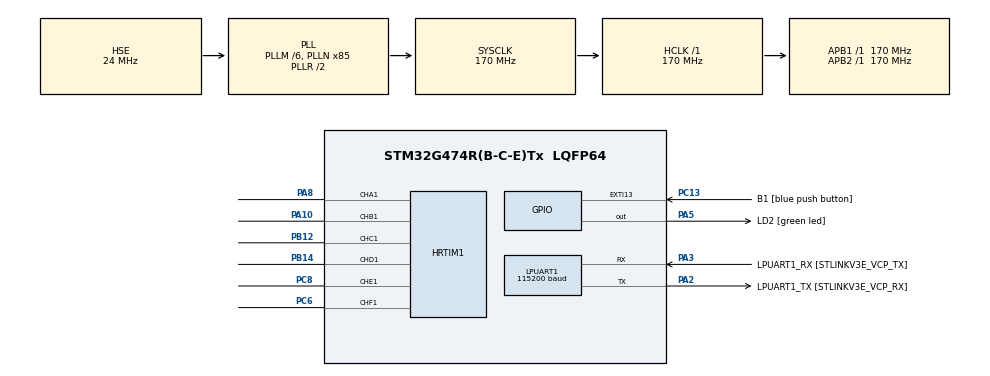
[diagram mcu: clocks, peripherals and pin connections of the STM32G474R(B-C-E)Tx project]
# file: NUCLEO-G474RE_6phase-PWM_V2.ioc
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Mcu.Family=STM32G4
HRTIM1.CompareValue1-Output_TA1=14166/6
HRTIM1.NumberSetSource1-Output_TE1=1
PB12.GPIO_Speed_High_Default=GPIO_SPEED_FREQ_LOW
RCC.CortexFreq_Value=170000000
HRTIM1.ResetTrigger2-Output_TF1=HRTIM_TIMRESETTRIGGER_OTHER4_CMP1
HRTIM1.CompareUnit2-Output_TB1=HRTIM_COMPAREUNIT_2
PC6.GPIO_Speed_High_Default=GPIO_SPEED_FREQ_LOW
HRTIM1.ResetTrigger1-Output_TD1=HRTIM_TIMRESETTRIGGER_OTHER3_CMP1
HRTIM1.CompareValue2-Output_TD1=50
PA14.GPIO_Label=T_SWCLK
HRTIM1.CompareValue1-Output_TB1=14166/6
HRTIM1.NumberSetSource1-Output_TD1=1
LPUART1.WordLength=UART_WORDLENGTH_8B
PC13.GPIO_Label=B1 [blue push button]
HRTIM1.CompareUnit2-Output_TC1=HRTIM_COMPAREUNIT_2
HRTIM1.CompareUnit4-Output_TF1=HRTIM_COMPAREUNIT_4
RCC.SYSCLKSource=RCC_SYSCLKSOURCE_PLLCLK
ProjectManager.StackSize=0x400
HRTIM1.ResetTrigger1-Output_TE1=HRTIM_TIMRESETTRIGGER_OTHER4_CMP1
HRTIM1.CompareValue2-Output_TE1=50
HRTIM1.NumberSetSource1-Output_TC1=1
HRTIM1.NumberResetSource1-Output_TF1=1
HRTIM1.CompareUnit2-Output_TD1=HRTIM_COMPAREUNIT_2
HRTIM1.CompareUnit4-Output_TE1=HRTIM_COMPAREUNIT_4
HRTIM1.CompareValue2-Output_TF1=50
HRTIM1.Periode_MASTER=14166
HRTIM1.ResetTrigger1-Output_TF1=HRTIM_TIMRESETTRIGGER_OTHER4_CMP1
RCC.HCLKFreq_Value=170000000
RCC.APB2TimFreq_Value=170000000
HRTIM1.NumberSetSource1-Output_TB1=1
HRTIM1.CompareUnit2-Output_TE1=HRTIM_COMPAREUNIT_2
RCC.AHBFreq_Value=170000000
HRTIM1.NumberResetSource1-Output_TE1=1
VP_HRTIM1_VS_hrtimMasterTimerNoOutput.Mode=MasterTimer
HRTIM1.CompareUnit4-Output_TD1=HRTIM_COMPAREUNIT_4
NVIC.EXTI15_10_IRQn=true\:0\:0\:false\:false\:true\:true\:true
RCC.HSE_VALUE=24000000
PB3.Mode=JTAG_5_pins
HRTIM1.CompareValue4-Output_TF1=14166/3
HRTIM1.ResetTrigger3-Output_TF1=HRTIM_TIMRESETTRIGGER_OTHER4_CMP4
HRTIM1.ResetOutput1_Source1-Output_TF1=HRTIM_OUTPUTRESET_TIMCMP4
PA15.Mode=JTAG_5_pins
RCC.ADC12Freq_Value=170000000
RCC.RTCClockSelection=RCC_RTCCLKSOURCE_LSE
HRTIM1.CompareUnit1-Output_TC1=HRTIM_COMPAREUNIT_1
HRTIM1.NumberSetSource1-Output_TA1=1
PB4.Mode=JTAG_5_pins
PC14-OSC32_IN.Mode=LSE-External-Oscillator
HRTIM1.NumberResetSource1-Output_TD1=1
HRTIM1.CompareUnit2-Output_TF1=HRTIM_COMPAREUNIT_2
PA14.Mode=JTAG_5_pins
PB14.Mode=Output_TD1
HRTIM1.PrescalerRatio_MASTER=HRTIM_PRESCALERRATIO_DIV1
VP_SYS_VS_DBSignals.Mode=DisableDeadBatterySignals
HRTIM1.CompareValue4-Output_TE1=14166/3
PA8.Signal=HRTIM1_CHA1
HRTIM1.CompareUnit1-Output_TD1=HRTIM_COMPAREUNIT_1
HRTIM1.ResetOutput1_Source1-Output_TE1=HRTIM_OUTPUTRESET_TIMCMP4
HRTIM1.NumberResetSource1-Output_TC1=1
HRTIM1.CompareValue2-Output_TA1=50
HRTIM1.ResetTrigger1-Output_TA1=HRTIM_TIMRESETTRIGGER_MASTER_PER
Mcu.Package=LQFP64
HRTIM1.CompareValue4-Output_TD1=14166/3
PB12.Mode=Output_TC1
HRTIM1.ResetOutput1_Source1-Output_TD1=HRTIM_OUTPUTRESET_TIMCMP4
PA2.GPIO_Label=LPUART1_TX [STLINKV3E_VCP_RX]
PA10.Signal=HRTIM1_CHB1
PA15.Signal=SYS_JTDI
HRTIM1.NumberResetTrigger-Output_TE1=1
HRTIM1.NumberResetSource1-Output_TB1=1
HRTIM1.ResetTrigger1-Output_TB1=HRTIM_TIMRESETTRIGGER_OTHER1_CMP1
HRTIM1.CompareValue4-Output_TC1=14166/3
HRTIM1.CompareValue2-Output_TB1=50
HRTIM1.SetOutput1_Source2-Output_TA1=HRTIM_OUTPUTSET_MASTERPER
RCC.APB1TimFreq_Value=170000000
HRTIM1.ResetOutput1_Source1-Output_TC1=HRTIM_OUTPUTRESET_TIMCMP4
HRTIM1.CompareUnit1-Output_TB1=HRTIM_COMPAREUNIT_1
PF1-OSC_OUT.Mode=HSE-External-Oscillator
HRTIM1.NumberResetTrigger-Output_TF1=1
PF1-OSC_OUT.Signal=RCC_OSC_OUT
HRTIM1.CompareUnit2-MasterTimer=HRTIM_COMPAREUNIT_2
RCC.HSI48_VALUE=48000000
HRTIM1.CompareUnit1-Output_TA1=HRTIM_COMPAREUNIT_1
HRTIM1.ResetTrigger1-Output_TC1=HRTIM_TIMRESETTRIGGER_OTHER2_CMP1
PB4.Signal=SYS_JTRST
HRTIM1.CompareValue4-Output_TB1=14166/3
PA3.Signal=LPUART1_RX
HRTIM1.NumberResetSource1-Output_TA1=1
HRTIM1.CompareValue2-Output_TC1=50
HRTIM1.SetOutput1_Source2-Output_TB1=HRTIM_OUTPUTSET_TIMBEV1_TIMACMP1
PB3.GPIO_Label=T_SWO
HRTIM1.SetOutput1_Source2-Output_TD1=HRTIM_OUTPUTSET_TIMPER
PA8.GPIO_Speed_High_Default=GPIO_SPEED_FREQ_LOW
RCC.PLLSourceVirtual=RCC_PLLSOURCE_HSE
PC15-OSC32_OUT.Mode=LSE-External-Oscillator
HRTIM1.ResetOutput1_Source1-Output_TB1=HRTIM_OUTPUTRESET_TIMCMP4
HRTIM1.SetOutput1_Source1-Output_TA1=HRTIM_OUTPUTSET_TIMCMP2
PA10.Mode=Output_TB1
HRTIM1.NumberResetTrigger-Output_TC1=1
HRTIM1.CompareValue4-Output_TA1=14166/3
PC13.Signal=GPXTI13
HRTIM1.SetOutput1_Source2-Output_TC1=HRTIM_OUTPUTSET_TIMPER
HRTIM1.SetOutput1_Source2-Output_TE1=HRTIM_OUTPUTSET_TIMPER
HRTIM1.ModeTimeBase-Output_TD1=HRTIM_MODE_SINGLESHOT_RETRIGGERABLE
PC8.Signal=HRTIM1_CHE1
PC6.Signal=HRTIM1_CHF1
RCC.EXTERNAL_CLOCK_VALUE=12288000
PA10.GPIO_Speed_High_Default=GPIO_SPEED_FREQ_LOW
HRTIM1.NumberUpdateTrigger-Output_TD1=0
HRTIM1.NumberResetTrigger-Output_TD1=1
PC14-OSC32_IN.Signal=RCC_OSC32_IN
HRTIM1.ResetOutput1_Source1-Output_TA1=HRTIM_OUTPUTRESET_TIMCMP4
HRTIM1.PrescalerRatio_TD=HRTIM_PRESCALERRATIO_DIV1
HRTIM1.PrescalerRatio_TE=HRTIM_PRESCALERRATIO_DIV1
HRTIM1.PrescalerRatio_TF=HRTIM_PRESCALERRATIO_DIV1
HRTIM1.SetOutput1_Source2-Output_TF1=HRTIM_OUTPUTSET_TIMPER
HRTIM1.ModeTimeBase-Output_TE1=HRTIM_MODE_SINGLESHOT_RETRIGGERABLE
HRTIM1.PrescalerRatio_TA=HRTIM_PRESCALERRATIO_DIV1
HRTIM1.CompareUnit1-Output_TE1=HRTIM_COMPAREUNIT_1
HRTIM1.PrescalerRatio_TB=HRTIM_PRESCALERRATIO_DIV1
HRTIM1.PrescalerRatio_TC=HRTIM_PRESCALERRATIO_DIV1
PA3.Mode=Asynchronous
PA13.Signal=SYS_JTMS-SWDIO
HRTIM1.NumberResetTrigger-Output_TA1=1
ProjectManager.TargetToolchain=STM32CubeIDE
PC6.Mode=Output_TF1
HRTIM1.CompareUnit1-Output_TF1=HRTIM_COMPAREUNIT_1
HRTIM1.ModeTimeBase-Output_TF1=HRTIM_MODE_SINGLESHOT_RETRIGGERABLE
RCC.USBFreq_Value=170000000
PC15-OSC32_OUT.Signal=RCC_OSC32_OUT
PF0-OSC_IN.Mode=HSE-External-Oscillator
HRTIM1.CompareValue1-MasterTimer=1700
HRTIM1.CompareValue2-MasterTimer=1700*6
PB14.Signal=HRTIM1_CHD1
HRTIM1.NumberResetTrigger-Output_TB1=1
PA5.Signal=GPIO_Output
board=NUCLEO-G474RE
RCC.VCOOutputFreq_Value=340000000
RCC.ADC345Freq_Value=170000000
HRTIM1.ResetTrigger2-Output_TB1=HRTIM_TIMRESETTRIGGER_UPDATE
RCC.APB2Freq_Value=170000000
HRTIM1.CompareValue1-Output_TE1=14166/6
HRTIM1.SetOutput1_Source1-Output_TF1=HRTIM_OUTPUTSET_TIMCMP2
HRTIM1.CompareUnit4-Output_TC1=HRTIM_COMPAREUNIT_4
PA13.Mode=JTAG_5_pins
HRTIM1.ResetTrigger2-Output_TA1=HRTIM_TIMRESETTRIGGER_UPDATE
Mcu.Name=STM32G474R(B-C-E)Tx
HRTIM1.SetOutput1_Source1-Output_TD1=HRTIM_OUTPUTSET_TIMCMP2
HRTIM1.CompareValue1-Output_TF1=14166/6
LPUART1.BaudRate=115200
PA2.Signal=LPUART1_TX
PA13.GPIO_Label=T_SWDIO
HRTIM1.SetOutput1_Source1-Output_TE1=HRTIM_OUTPUTSET_TIMCMP2
HRTIM1.CompareUnit4-Output_TB1=HRTIM_COMPAREUNIT_4
PC8.Mode=Output_TE1
PC8.GPIO_Speed_High_Default=GPIO_SPEED_FREQ_LOW
PB3.Signal=SYS_JTDO-SWO
RCC.SYSCLKFreq_VALUE=170000000
HRTIM1.ModeTimeBase-Output_TA1=HRTIM_MODE_SINGLESHOT_RETRIGGERABLE
PA5.GPIO_Label=LD2 [green led]
HRTIM1.SetOutput1_Source1-Output_TC1=HRTIM_OUTPUTSET_TIMCMP2
HRTIM1.CompareValue1-Output_TC1=14166/6
PA14.Signal=SYS_JTCK-SWCLK
ProjectManager.HeapSize=0x200
HRTIM1.CompareUnit4-Output_TA1=HRTIM_COMPAREUNIT_4
RCC.HSI_VALUE=16000000
NVIC.PriorityGroup=NVIC_PRIORITYGROUP_4
RCC.PLLM=RCC_PLLM_DIV6
RCC.PLLN=85
PA2.Mode=Asynchronous
PA8.Mode=Output_TA1
HRTIM1.NumberSetSource1-Output_TF1=1
PB14.GPIO_Speed_High_Default=GPIO_SPEED_FREQ_LOW
PF0-OSC_IN.Signal=RCC_OSC_IN
HRTIM1.ResetTrigger2-Output_TC1=HRTIM_TIMRESETTRIGGER_OTHER2_CMP1
HRTIM1.CompareValue1-Output_TD1=14166/6
RCC.APB1Freq_Value=170000000
HRTIM1.SetOutput1_Source1-Output_TB1=HRTIM_OUTPUTSET_TIMCMP2
HRTIM1.SetOutput1_Source3-Output_TA1=HRTIM_OUTPUTSET_MASTERPER
HRTIM1.Periode_TA=14166
HRTIM1.CompareUnit1-MasterTimer=HRTIM_COMPAREUNIT_1
HRTIM1.Periode_TB=14166
HRTIM1.CompareUnit2-Output_TA1=HRTIM_COMPAREUNIT_2
HRTIM1.Periode_TC=14166
HRTIM1.Periode_TD=14166
PB12.Signal=HRTIM1_CHC1
HRTIM1.Periode_TE=14166
HRTIM1.Periode_TF=14166
PA3.GPIO_Label=LPUART1_RX [STLINKV3E_VCP_TX]

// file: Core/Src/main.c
/* USER CODE BEGIN Header */
/**
  ******************************************************************************
  * @file           : main.c
  * @brief          : Main program body
  ******************************************************************************
  * @attention
  *
  * <h2><center>&copy; Copyright (c) 2021 STMicroelectronics.
  * All rights reserved.</center></h2>
  *
  * This software component is licensed by ST under BSD 3-Clause license,
  * the "License"; You may not use this file except in compliance with the
  * License. You may obtain a copy of the License at:
  *                        opensource.org/licenses/BSD-3-Clause
  *
  ******************************************************************************
  */
/* USER CODE END Header */
#include "main.h"

HRTIM_HandleTypeDef hhrtim1;

UART_HandleTypeDef hlpuart1;

void SystemClock_Config(void);
static void MX_GPIO_Init(void);
static void MX_LPUART1_UART_Init(void);
static void MX_HRTIM1_Init(void);

int main(void)
{

  /* MCU Configuration--------------------------------------------------------*/

  /* Reset of all peripherals, Initializes the Flash interface and the Systick. */
  HAL_Init();

  /* Configure the system clock */
  SystemClock_Config();

  /* Initialize all configured peripherals */
  MX_GPIO_Init();
  MX_LPUART1_UART_Init();
  MX_HRTIM1_Init();
  /* USER CODE BEGIN 2 */

  HAL_HRTIM_WaveformOutputStart(&hhrtim1, HRTIM_OUTPUT_TA1 | HRTIM_OUTPUT_TB1 | HRTIM_OUTPUT_TC1 | HRTIM_OUTPUT_TD1 | HRTIM_OUTPUT_TE1 | HRTIM_OUTPUT_TF1);
  HAL_HRTIM_WaveformCountStart_IT(&hhrtim1, HRTIM_TIMERID_MASTER | HRTIM_TIMERID_TIMER_A | HRTIM_TIMERID_TIMER_B | HRTIM_TIMERID_TIMER_C | HRTIM_TIMERID_TIMER_D | HRTIM_TIMERID_TIMER_E |HRTIM_TIMERID_TIMER_F);

  /* USER CODE END 2 */

  /* Infinite loop */
  while (1)
  {

  }
}

void SystemClock_Config(void)
{
  RCC_OscInitTypeDef RCC_OscInitStruct = {0};
  RCC_ClkInitTypeDef RCC_ClkInitStruct = {0};
  RCC_PeriphCLKInitTypeDef PeriphClkInit = {0};

  /** Configure the main internal regulator output voltage
  */
  HAL_PWREx_ControlVoltageScaling(PWR_REGULATOR_VOLTAGE_SCALE1_BOOST);
  /** Initializes the RCC Oscillators according to the specified parameters
  * in the RCC_OscInitTypeDef structure.
  */
  RCC_OscInitStruct.OscillatorType = RCC_OSCILLATORTYPE_HSE;
  RCC_OscInitStruct.HSEState = RCC_HSE_ON;
  RCC_OscInitStruct.PLL.PLLState = RCC_PLL_ON;
  RCC_OscInitStruct.PLL.PLLSource = RCC_PLLSOURCE_HSE;
  RCC_OscInitStruct.PLL.PLLM = RCC_PLLM_DIV6;
  RCC_OscInitStruct.PLL.PLLN = 85;
  RCC_OscInitStruct.PLL.PLLP = RCC_PLLP_DIV2;
  RCC_OscInitStruct.PLL.PLLQ = RCC_PLLQ_DIV2;
  RCC_OscInitStruct.PLL.PLLR = RCC_PLLR_DIV2;
  if (HAL_RCC_OscConfig(&RCC_OscInitStruct) != HAL_OK)
  {
    Error_Handler();
  }
  /** Initializes the CPU, AHB and APB buses clocks
  */
  RCC_ClkInitStruct.ClockType = RCC_CLOCKTYPE_HCLK|RCC_CLOCKTYPE_SYSCLK
                              |RCC_CLOCKTYPE_PCLK1|RCC_CLOCKTYPE_PCLK2;
  RCC_ClkInitStruct.SYSCLKSource = RCC_SYSCLKSOURCE_PLLCLK;
  RCC_ClkInitStruct.AHBCLKDivider = RCC_SYSCLK_DIV1;
  RCC_ClkInitStruct.APB1CLKDivider = RCC_HCLK_DIV1;
  RCC_ClkInitStruct.APB2CLKDivider = RCC_HCLK_DIV1;

  if (HAL_RCC_ClockConfig(&RCC_ClkInitStruct, FLASH_LATENCY_4) != HAL_OK)
  {
    Error_Handler();
  }
  /** Initializes the peripherals clocks
  */
  PeriphClkInit.PeriphClockSelection = RCC_PERIPHCLK_LPUART1;
  PeriphClkInit.Lpuart1ClockSelection = RCC_LPUART1CLKSOURCE_PCLK1;
  if (HAL_RCCEx_PeriphCLKConfig(&PeriphClkInit) != HAL_OK)
  {
    Error_Handler();
  }
}

static void MX_HRTIM1_Init(void)
{

  HRTIM_TimeBaseCfgTypeDef pTimeBaseCfg = {0};
  HRTIM_TimerCfgTypeDef pTimerCfg = {0};
  HRTIM_CompareCfgTypeDef pCompareCfg = {0};
  HRTIM_TimerCtlTypeDef pTimerCtl = {0};
  HRTIM_OutputCfgTypeDef pOutputCfg = {0};

  hhrtim1.Instance = HRTIM1;
  hhrtim1.Init.HRTIMInterruptResquests = HRTIM_IT_NONE;
  hhrtim1.Init.SyncOptions = HRTIM_SYNCOPTION_NONE;
  if (HAL_HRTIM_Init(&hhrtim1) != HAL_OK)
  {
    Error_Handler();
  }
  if (HAL_HRTIM_DLLCalibrationStart(&hhrtim1, HRTIM_CALIBRATIONRATE_3) != HAL_OK)
  {
    Error_Handler();
  }
  if (HAL_HRTIM_PollForDLLCalibration(&hhrtim1, 10) != HAL_OK)
  {
    Error_Handler();
  }
  pTimeBaseCfg.Period = 14166;
  pTimeBaseCfg.RepetitionCounter = 0x00;
  pTimeBaseCfg.PrescalerRatio = HRTIM_PRESCALERRATIO_DIV1;
  pTimeBaseCfg.Mode = HRTIM_MODE_CONTINUOUS;
  if (HAL_HRTIM_TimeBaseConfig(&hhrtim1, HRTIM_TIMERINDEX_MASTER, &pTimeBaseCfg) != HAL_OK)
  {
    Error_Handler();
  }
  pTimerCfg.InterruptRequests = HRTIM_MASTER_IT_NONE;
  pTimerCfg.DMARequests = HRTIM_MASTER_DMA_NONE;
  pTimerCfg.DMASrcAddress = 0x0000;
  pTimerCfg.DMADstAddress = 0x0000;
  pTimerCfg.DMASize = 0x1;
  pTimerCfg.HalfModeEnable = HRTIM_HALFMODE_DISABLED;
  pTimerCfg.InterleavedMode = HRTIM_INTERLEAVED_MODE_DISABLED;
  pTimerCfg.StartOnSync = HRTIM_SYNCSTART_DISABLED;
  pTimerCfg.ResetOnSync = HRTIM_SYNCRESET_DISABLED;
  pTimerCfg.DACSynchro = HRTIM_DACSYNC_NONE;
  pTimerCfg.PreloadEnable = HRTIM_PRELOAD_DISABLED;
  pTimerCfg.UpdateGating = HRTIM_UPDATEGATING_INDEPENDENT;
  pTimerCfg.BurstMode = HRTIM_TIMERBURSTMODE_MAINTAINCLOCK;
  pTimerCfg.RepetitionUpdate = HRTIM_UPDATEONREPETITION_DISABLED;
  pTimerCfg.ReSyncUpdate = HRTIM_TIMERESYNC_UPDATE_UNCONDITIONAL;
  if (HAL_HRTIM_WaveformTimerConfig(&hhrtim1, HRTIM_TIMERINDEX_MASTER, &pTimerCfg) != HAL_OK)
  {
    Error_Handler();
  }
  pCompareCfg.CompareValue = 1700;
  if (HAL_HRTIM_WaveformCompareConfig(&hhrtim1, HRTIM_TIMERINDEX_MASTER, HRTIM_COMPAREUNIT_1, &pCompareCfg) != HAL_OK)
  {
    Error_Handler();
  }
  pCompareCfg.CompareValue = 1700*6;
  if (HAL_HRTIM_WaveformCompareConfig(&hhrtim1, HRTIM_TIMERINDEX_MASTER, HRTIM_COMPAREUNIT_2, &pCompareCfg) != HAL_OK)
  {
    Error_Handler();
  }
  pTimeBaseCfg.Mode = HRTIM_MODE_SINGLESHOT_RETRIGGERABLE;
  if (HAL_HRTIM_TimeBaseConfig(&hhrtim1, HRTIM_TIMERINDEX_TIMER_A, &pTimeBaseCfg) != HAL_OK)
  {
    Error_Handler();
  }
  pTimerCtl.UpDownMode = HRTIM_TIMERUPDOWNMODE_UP;
  pTimerCtl.TrigHalf = HRTIM_TIMERTRIGHALF_DISABLED;
  pTimerCtl.GreaterCMP1 = HRTIM_TIMERGTCMP1_EQUAL;
  pTimerCtl.DualChannelDacEnable = HRTIM_TIMER_DCDE_DISABLED;
  if (HAL_HRTIM_WaveformTimerControl(&hhrtim1, HRTIM_TIMERINDEX_TIMER_A, &pTimerCtl) != HAL_OK)
  {
    Error_Handler();
  }
  pTimerCfg.InterruptRequests = HRTIM_TIM_IT_NONE;
  pTimerCfg.DMARequests = HRTIM_TIM_DMA_NONE;
  pTimerCfg.PushPull = HRTIM_TIMPUSHPULLMODE_DISABLED;
  pTimerCfg.FaultEnable = HRTIM_TIMFAULTENABLE_NONE;
  pTimerCfg.FaultLock = HRTIM_TIMFAULTLOCK_READWRITE;
  pTimerCfg.DeadTimeInsertion = HRTIM_TIMDEADTIMEINSERTION_DISABLED;
  pTimerCfg.DelayedProtectionMode = HRTIM_TIMER_A_B_C_DELAYEDPROTECTION_DISABLED;
  pTimerCfg.UpdateTrigger = HRTIM_TIMUPDATETRIGGER_NONE;
  pTimerCfg.ResetTrigger = HRTIM_TIMRESETTRIGGER_MASTER_PER;
  pTimerCfg.ResetUpdate = HRTIM_TIMUPDATEONRESET_DISABLED;
  if (HAL_HRTIM_WaveformTimerConfig(&hhrtim1, HRTIM_TIMERINDEX_TIMER_A, &pTimerCfg) != HAL_OK)
  {
    Error_Handler();
  }
  pTimerCfg.ResetTrigger = HRTIM_TIMRESETTRIGGER_OTHER1_CMP1;
  if (HAL_HRTIM_WaveformTimerConfig(&hhrtim1, HRTIM_TIMERINDEX_TIMER_B, &pTimerCfg) != HAL_OK)
  {
    Error_Handler();
  }
  pTimerCfg.ResetTrigger = HRTIM_TIMRESETTRIGGER_OTHER2_CMP1;
  if (HAL_HRTIM_WaveformTimerConfig(&hhrtim1, HRTIM_TIMERINDEX_TIMER_C, &pTimerCfg) != HAL_OK)
  {
    Error_Handler();
  }
  pTimerCfg.DelayedProtectionMode = HRTIM_TIMER_D_E_DELAYEDPROTECTION_DISABLED;
  pTimerCfg.ResetTrigger = HRTIM_TIMRESETTRIGGER_OTHER3_CMP1;
  if (HAL_HRTIM_WaveformTimerConfig(&hhrtim1, HRTIM_TIMERINDEX_TIMER_D, &pTimerCfg) != HAL_OK)
  {
    Error_Handler();
  }
  pTimerCfg.InterruptRequests = HRTIM_MASTER_IT_NONE;
  pTimerCfg.ResetTrigger = HRTIM_TIMRESETTRIGGER_OTHER4_CMP1;
  if (HAL_HRTIM_WaveformTimerConfig(&hhrtim1, HRTIM_TIMERINDEX_TIMER_E, &pTimerCfg) != HAL_OK)
  {
    Error_Handler();
  }
  pTimerCfg.InterruptRequests = HRTIM_TIM_IT_NONE;
  pTimerCfg.DelayedProtectionMode = HRTIM_TIMER_F_DELAYEDPROTECTION_DISABLED;
  pTimerCfg.ResetTrigger = HRTIM_TIMRESETTRIGGER_OTHER5_CMP1;
  if (HAL_HRTIM_WaveformTimerConfig(&hhrtim1, HRTIM_TIMERINDEX_TIMER_F, &pTimerCfg) != HAL_OK)
  {
    Error_Handler();
  }
  pCompareCfg.CompareValue = 14166/6;
  if (HAL_HRTIM_WaveformCompareConfig(&hhrtim1, HRTIM_TIMERINDEX_TIMER_A, HRTIM_COMPAREUNIT_1, &pCompareCfg) != HAL_OK)
  {
    Error_Handler();
  }
  pCompareCfg.CompareValue = 50;
  pCompareCfg.AutoDelayedMode = HRTIM_AUTODELAYEDMODE_REGULAR;
  pCompareCfg.AutoDelayedTimeout = 0x0000;

  if (HAL_HRTIM_WaveformCompareConfig(&hhrtim1, HRTIM_TIMERINDEX_TIMER_A, HRTIM_COMPAREUNIT_2, &pCompareCfg) != HAL_OK)
  {
    Error_Handler();
  }
  pCompareCfg.CompareValue = 14166/3;

  if (HAL_HRTIM_WaveformCompareConfig(&hhrtim1, HRTIM_TIMERINDEX_TIMER_A, HRTIM_COMPAREUNIT_4, &pCompareCfg) != HAL_OK)
  {
    Error_Handler();
  }

  if (HAL_HRTIM_WaveformCompareConfig(&hhrtim1, HRTIM_TIMERINDEX_TIMER_B, HRTIM_COMPAREUNIT_4, &pCompareCfg) != HAL_OK)
  {
    Error_Handler();
  }

  if (HAL_HRTIM_WaveformCompareConfig(&hhrtim1, HRTIM_TIMERINDEX_TIMER_C, HRTIM_COMPAREUNIT_4, &pCompareCfg) != HAL_OK)
  {
    Error_Handler();
  }

  if (HAL_HRTIM_WaveformCompareConfig(&hhrtim1, HRTIM_TIMERINDEX_TIMER_D, HRTIM_COMPAREUNIT_4, &pCompareCfg) != HAL_OK)
  {
    Error_Handler();
  }

  if (HAL_HRTIM_WaveformCompareConfig(&hhrtim1, HRTIM_TIMERINDEX_TIMER_E, HRTIM_COMPAREUNIT_4, &pCompareCfg) != HAL_OK)
  {
    Error_Handler();
  }

  if (HAL_HRTIM_WaveformCompareConfig(&hhrtim1, HRTIM_TIMERINDEX_TIMER_F, HRTIM_COMPAREUNIT_4, &pCompareCfg) != HAL_OK)
  {
    Error_Handler();
  }
  pOutputCfg.Polarity = HRTIM_OUTPUTPOLARITY_HIGH;
  pOutputCfg.SetSource = HRTIM_OUTPUTSET_TIMCMP2;
  pOutputCfg.ResetSource = HRTIM_OUTPUTRESET_TIMCMP4;
  pOutputCfg.IdleMode = HRTIM_OUTPUTIDLEMODE_NONE;
  pOutputCfg.IdleLevel = HRTIM_OUTPUTIDLELEVEL_INACTIVE;
  pOutputCfg.FaultLevel = HRTIM_OUTPUTFAULTLEVEL_NONE;
  pOutputCfg.ChopperModeEnable = HRTIM_OUTPUTCHOPPERMODE_DISABLED;
  pOutputCfg.BurstModeEntryDelayed = HRTIM_OUTPUTBURSTMODEENTRY_REGULAR;
  if (HAL_HRTIM_WaveformOutputConfig(&hhrtim1, HRTIM_TIMERINDEX_TIMER_A, HRTIM_OUTPUT_TA1, &pOutputCfg) != HAL_OK)
  {
    Error_Handler();
  }
  if (HAL_HRTIM_WaveformOutputConfig(&hhrtim1, HRTIM_TIMERINDEX_TIMER_B, HRTIM_OUTPUT_TB1, &pOutputCfg) != HAL_OK)
  {
    Error_Handler();
  }
  if (HAL_HRTIM_WaveformOutputConfig(&hhrtim1, HRTIM_TIMERINDEX_TIMER_C, HRTIM_OUTPUT_TC1, &pOutputCfg) != HAL_OK)
  {
    Error_Handler();
  }
  if (HAL_HRTIM_WaveformOutputConfig(&hhrtim1, HRTIM_TIMERINDEX_TIMER_D, HRTIM_OUTPUT_TD1, &pOutputCfg) != HAL_OK)
  {
    Error_Handler();
  }
  if (HAL_HRTIM_WaveformOutputConfig(&hhrtim1, HRTIM_TIMERINDEX_TIMER_E, HRTIM_OUTPUT_TE1, &pOutputCfg) != HAL_OK)
  {
    Error_Handler();
  }
  if (HAL_HRTIM_WaveformOutputConfig(&hhrtim1, HRTIM_TIMERINDEX_TIMER_F, HRTIM_OUTPUT_TF1, &pOutputCfg) != HAL_OK)
  {
    Error_Handler();
  }
  pTimeBaseCfg.Mode = HRTIM_MODE_CONTINUOUS;
  if (HAL_HRTIM_TimeBaseConfig(&hhrtim1, HRTIM_TIMERINDEX_TIMER_B, &pTimeBaseCfg) != HAL_OK)
  {
    Error_Handler();
  }
  if (HAL_HRTIM_WaveformTimerControl(&hhrtim1, HRTIM_TIMERINDEX_TIMER_B, &pTimerCtl) != HAL_OK)
  {
    Error_Handler();
  }
  pCompareCfg.CompareValue = 14166/6;
  if (HAL_HRTIM_WaveformCompareConfig(&hhrtim1, HRTIM_TIMERINDEX_TIMER_B, HRTIM_COMPAREUNIT_1, &pCompareCfg) != HAL_OK)
  {
    Error_Handler();
  }
  pCompareCfg.CompareValue = 50;

  if (HAL_HRTIM_WaveformCompareConfig(&hhrtim1, HRTIM_TIMERINDEX_TIMER_B, HRTIM_COMPAREUNIT_2, &pCompareCfg) != HAL_OK)
  {
    Error_Handler();
  }
  if (HAL_HRTIM_TimeBaseConfig(&hhrtim1, HRTIM_TIMERINDEX_TIMER_C, &pTimeBaseCfg) != HAL_OK)
  {
    Error_Handler();
  }
  if (HAL_HRTIM_WaveformTimerControl(&hhrtim1, HRTIM_TIMERINDEX_TIMER_C, &pTimerCtl) != HAL_OK)
  {
    Error_Handler();
  }
  pCompareCfg.CompareValue = 14166/6;
  if (HAL_HRTIM_WaveformCompareConfig(&hhrtim1, HRTIM_TIMERINDEX_TIMER_C, HRTIM_COMPAREUNIT_1, &pCompareCfg) != HAL_OK)
  {
    Error_Handler();
  }
  pCompareCfg.CompareValue = 50;

  if (HAL_HRTIM_WaveformCompareConfig(&hhrtim1, HRTIM_TIMERINDEX_TIMER_C, HRTIM_COMPAREUNIT_2, &pCompareCfg) != HAL_OK)
  {
    Error_Handler();
  }
  pTimeBaseCfg.Mode = HRTIM_MODE_SINGLESHOT_RETRIGGERABLE;
  if (HAL_HRTIM_TimeBaseConfig(&hhrtim1, HRTIM_TIMERINDEX_TIMER_D, &pTimeBaseCfg) != HAL_OK)
  {
    Error_Handler();
  }
  if (HAL_HRTIM_WaveformTimerControl(&hhrtim1, HRTIM_TIMERINDEX_TIMER_D, &pTimerCtl) != HAL_OK)
  {
    Error_Handler();
  }
  pCompareCfg.CompareValue = 14166/6;
  if (HAL_HRTIM_WaveformCompareConfig(&hhrtim1, HRTIM_TIMERINDEX_TIMER_D, HRTIM_COMPAREUNIT_1, &pCompareCfg) != HAL_OK)
  {
    Error_Handler();
  }
  pCompareCfg.CompareValue = 50;

  if (HAL_HRTIM_WaveformCompareConfig(&hhrtim1, HRTIM_TIMERINDEX_TIMER_D, HRTIM_COMPAREUNIT_2, &pCompareCfg) != HAL_OK)
  {
    Error_Handler();
  }
  if (HAL_HRTIM_TimeBaseConfig(&hhrtim1, HRTIM_TIMERINDEX_TIMER_E, &pTimeBaseCfg) != HAL_OK)
  {
    Error_Handler();
  }
  if (HAL_HRTIM_WaveformTimerControl(&hhrtim1, HRTIM_TIMERINDEX_TIMER_E, &pTimerCtl) != HAL_OK)
  {
    Error_Handler();
  }
  pCompareCfg.CompareValue = 14166/6;
  if (HAL_HRTIM_WaveformCompareConfig(&hhrtim1, HRTIM_TIMERINDEX_TIMER_E, HRTIM_COMPAREUNIT_1, &pCompareCfg) != HAL_OK)
  {
    Error_Handler();
  }
  pCompareCfg.CompareValue = 50;

  if (HAL_HRTIM_WaveformCompareConfig(&hhrtim1, HRTIM_TIMERINDEX_TIMER_E, HRTIM_COMPAREUNIT_2, &pCompareCfg) != HAL_OK)
  {
    Error_Handler();
  }
  if (HAL_HRTIM_TimeBaseConfig(&hhrtim1, HRTIM_TIMERINDEX_TIMER_F, &pTimeBaseCfg) != HAL_OK)
  {
    Error_Handler();
  }
  if (HAL_HRTIM_WaveformTimerControl(&hhrtim1, HRTIM_TIMERINDEX_TIMER_F, &pTimerCtl) != HAL_OK)
  {
    Error_Handler();
  }
  pCompareCfg.CompareValue = 14166/6;
  if (HAL_HRTIM_WaveformCompareConfig(&hhrtim1, HRTIM_TIMERINDEX_TIMER_F, HRTIM_COMPAREUNIT_1, &pCompareCfg) != HAL_OK)
  {
    Error_Handler();
  }
  pCompareCfg.CompareValue = 50;

  if (HAL_HRTIM_WaveformCompareConfig(&hhrtim1, HRTIM_TIMERINDEX_TIMER_F, HRTIM_COMPAREUNIT_2, &pCompareCfg) != HAL_OK)
  {
    Error_Handler();
  }
  HAL_HRTIM_MspPostInit(&hhrtim1);

}

static void MX_LPUART1_UART_Init(void)
{

  hlpuart1.Instance = LPUART1;
  hlpuart1.Init.BaudRate = 115200;
  hlpuart1.Init.WordLength = UART_WORDLENGTH_8B;
  hlpuart1.Init.StopBits = UART_STOPBITS_1;
  hlpuart1.Init.Parity = UART_PARITY_NONE;
  hlpuart1.Init.Mode = UART_MODE_TX_RX;
  hlpuart1.Init.HwFlowCtl = UART_HWCONTROL_NONE;
  hlpuart1.Init.OneBitSampling = UART_ONE_BIT_SAMPLE_DISABLE;
  hlpuart1.Init.ClockPrescaler = UART_PRESCALER_DIV1;
  hlpuart1.AdvancedInit.AdvFeatureInit = UART_ADVFEATURE_NO_INIT;
  if (HAL_UART_Init(&hlpuart1) != HAL_OK)
  {
    Error_Handler();
  }
  if (HAL_UARTEx_SetTxFifoThreshold(&hlpuart1, UART_TXFIFO_THRESHOLD_1_8) != HAL_OK)
  {
    Error_Handler();
  }
  if (HAL_UARTEx_SetRxFifoThreshold(&hlpuart1, UART_RXFIFO_THRESHOLD_1_8) != HAL_OK)
  {
    Error_Handler();
  }
  if (HAL_UARTEx_DisableFifoMode(&hlpuart1) != HAL_OK)
  {
    Error_Handler();
  }

}

static void MX_GPIO_Init(void)
{
  GPIO_InitTypeDef GPIO_InitStruct = {0};

  /* GPIO Ports Clock Enable */
  __HAL_RCC_GPIOC_CLK_ENABLE();
  __HAL_RCC_GPIOF_CLK_ENABLE();
  __HAL_RCC_GPIOA_CLK_ENABLE();
  __HAL_RCC_GPIOB_CLK_ENABLE();

  /*Configure GPIO pin Output Level */
  HAL_GPIO_WritePin(LD2_GPIO_Port, LD2_Pin, GPIO_PIN_RESET);

  /*Configure GPIO pin : B1_Pin */
  GPIO_InitStruct.Pin = B1_Pin;
  GPIO_InitStruct.Mode = GPIO_MODE_IT_RISING;
  GPIO_InitStruct.Pull = GPIO_NOPULL;
  HAL_GPIO_Init(B1_GPIO_Port, &GPIO_InitStruct);

  /*Configure GPIO pin : LD2_Pin */
  GPIO_InitStruct.Pin = LD2_Pin;
  GPIO_InitStruct.Mode = GPIO_MODE_OUTPUT_PP;
  GPIO_InitStruct.Pull = GPIO_NOPULL;
  GPIO_InitStruct.Speed = GPIO_SPEED_FREQ_LOW;
  HAL_GPIO_Init(LD2_GPIO_Port, &GPIO_InitStruct);

  /* EXTI interrupt init*/
  HAL_NVIC_SetPriority(EXTI15_10_IRQn, 0, 0);
  HAL_NVIC_EnableIRQ(EXTI15_10_IRQn);

}

void Error_Handler(void)
{
  __disable_irq();
  while (1)
  {
  }
}

/************************ (C) COPYRIGHT STMicroelectronics *****END OF FILE****/
